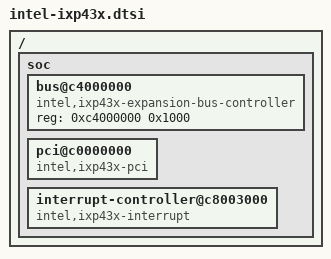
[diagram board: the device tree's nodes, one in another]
#include "intel-ixp4xx.dtsi"
/ {
	soc {
		bus@c4000000 {
			compatible = "intel,ixp43x-expansion-bus-controller", "syscon";
			reg = <0xc4000000 0x1000>;
		};
		pci@c0000000 {
			compatible = "intel,ixp43x-pci";
		};
		interrupt-controller@c8003000 {
			compatible = "intel,ixp43x-interrupt";
		};
	};
};
